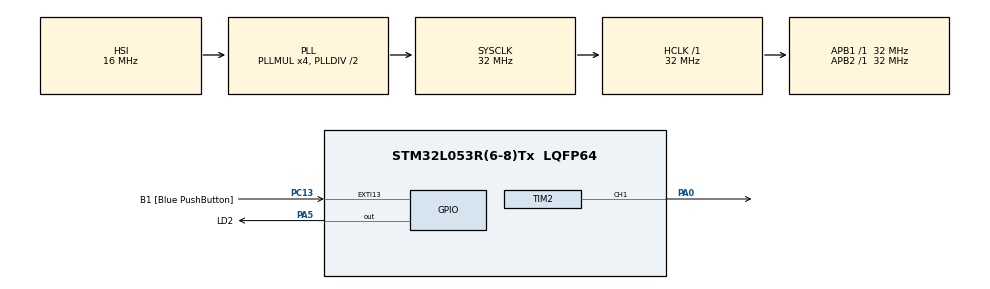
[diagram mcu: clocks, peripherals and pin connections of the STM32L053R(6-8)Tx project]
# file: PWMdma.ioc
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Dma.Request0=TIM2_CH1
Dma.TIM2_CH1.0.Direction=DMA_MEMORY_TO_PERIPH
Dma.TIM2_CH1.0.Instance=DMA1_Channel5
Dma.TIM2_CH1.0.MemDataAlignment=DMA_MDATAALIGN_HALFWORD
Dma.TIM2_CH1.0.MemInc=DMA_MINC_ENABLE
Dma.TIM2_CH1.0.Mode=DMA_NORMAL
Dma.TIM2_CH1.0.PeriphDataAlignment=DMA_PDATAALIGN_HALFWORD
Dma.TIM2_CH1.0.PeriphInc=DMA_PINC_DISABLE
Dma.TIM2_CH1.0.Priority=DMA_PRIORITY_LOW
Dma.TIM2_CH1.0.Request=DMA_REQUEST_8
Mcu.Family=STM32L0
Mcu.Name=STM32L053R(6-8)Tx
Mcu.Package=LQFP64
NVIC.DMA1_Channel4_5_6_7_IRQn=true\:0\:0\:false
PA0.Signal=S_TIM2_CH1
PA13.GPIO_Label=TMS
PA13.Mode=Serial_Wire
PA13.Signal=SYS_SWDIO
PA14.GPIO_Label=TCK
PA14.Mode=Serial_Wire
PA14.Signal=SYS_SWCLK
PA2.GPIO_Label=USART_TX
PA2.Signal=USART2_TX
PA3.GPIO_Label=USART_RX
PA3.Signal=USART2_RX
PA5.GPIO_Label=LD2
PA5.Signal=GPIO_Output
PC13.GPIO_Label=B1 [Blue PushButton]
PC13.GPIO_ModeDefaultEXTI=GPIO_MODE_EVT_RISING
PC13.Signal=GPXTI13
PC14-OSC32_IN.Signal=RCC_OSC32_IN
PC15-OSC32_OUT.Signal=RCC_OSC32_OUT
PH0-OSC_IN.Signal=RCC_OSC_IN
PH1-OSC_OUT.Signal=RCC_OSC_OUT
ProjectManager.TargetToolchain=EWARM
RCC.AHBFreq_Value=32000000
RCC.APB1Freq_Value=32000000
RCC.APB1TimFreq_Value=32000000
RCC.APB2Freq_Value=32000000
RCC.APB2TimFreq_Value=32000000
RCC.HCLKFreq_Value=32000000
RCC.HSE_VALUE=8000000
RCC.HSI16_VALUE=16000000
RCC.HSI48_VALUE=48000000
RCC.HSI_VALUE=16000000
RCC.LSEState=RCC_LSE_ON
RCC.LSE_VALUE=32768
RCC.MSI_VALUE=2097000
RCC.PLLMUL=RCC_PLLMUL_4
RCC.SYSCLKFreq_VALUE=32000000
RCC.SYSCLKSource=RCC_SYSCLKSOURCE_PLLCLK
RCC.VCOOutputFreq_Value=64000000
SH.S_TIM2_CH1.0=TIM2_CH1,PWM Generation1 CH1
TIM2.OCFastMode_PWM-PWM\ Generation1\ CH1=TIM_OCFAST_DISABLE
TIM2.Period=38
TIM2.Prescaler=0
TIM2.Pulse-PWM\ Generation1\ CH1=0
TIM2.TIM_MasterOutputTrigger=TIM_TRGO_RESET
TIM2.TIM_MasterSlaveMode=TIM_MASTERSLAVEMODE_DISABLE
VP_TIM2_VS_ClockSourceINT.Mode=Internal
board=NUCLEO-L053R8

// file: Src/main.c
/**
  ******************************************************************************
  * File Name          : main.c
  * Description        : Main program body
  ******************************************************************************
  *
  * COPYRIGHT(c) 2016 STMicroelectronics
  *
  * Redistribution and use in source and binary forms, with or without modification,
  * are permitted provided that the following conditions are met:
  *   1. Redistributions of source code must retain the above copyright notice,
  *      this list of conditions and the following disclaimer.
  *   2. Redistributions in binary form must reproduce the above copyright notice,
  *      this list of conditions and the following disclaimer in the documentation
  *      and/or other materials provided with the distribution.
  *   3. Neither the name of STMicroelectronics nor the names of its contributors
  *      may be used to endorse or promote products derived from this software
  *      without specific prior written permission.
  *
  * THIS SOFTWARE IS PROVIDED BY THE COPYRIGHT HOLDERS AND CONTRIBUTORS "AS IS"
  * AND ANY EXPRESS OR IMPLIED WARRANTIES, INCLUDING, BUT NOT LIMITED TO, THE
  * IMPLIED WARRANTIES OF MERCHANTABILITY AND FITNESS FOR A PARTICULAR PURPOSE ARE
  * DISCLAIMED. IN NO EVENT SHALL THE COPYRIGHT HOLDER OR CONTRIBUTORS BE LIABLE
  * FOR ANY DIRECT, INDIRECT, INCIDENTAL, SPECIAL, EXEMPLARY, OR CONSEQUENTIAL
  * DAMAGES (INCLUDING, BUT NOT LIMITED TO, PROCUREMENT OF SUBSTITUTE GOODS OR
  * SERVICES; LOSS OF USE, DATA, OR PROFITS; OR BUSINESS INTERRUPTION) HOWEVER
  * CAUSED AND ON ANY THEORY OF LIABILITY, WHETHER IN CONTRACT, STRICT LIABILITY,
  * OR TORT (INCLUDING NEGLIGENCE OR OTHERWISE) ARISING IN ANY WAY OUT OF THE USE
  * OF THIS SOFTWARE, EVEN IF ADVISED OF THE POSSIBILITY OF SUCH DAMAGE.
  *
  ******************************************************************************
  */
#include "stm32l0xx_hal.h"
#include "dma.h"
#include "tim.h"
#include "gpio.h"

/* USER CODE BEGIN Includes */
#include <string.h>
/* USER CODE END Includes */

/* USER CODE BEGIN PV */
/* Private variables ---------------------------------------------------------*/

/* USER CODE END PV */

void SystemClock_Config(void);

/* USER CODE BEGIN PFP */
/* Private function prototypes -----------------------------------------------*/

/* USER CODE END PFP */

/* USER CODE BEGIN 0 */
#define H_VAL 26
#define L_VAL 14
#define N_LEDS 24
#define BITS_PER_LED (3*8)
#define BIT_BUF_SIZE (N_LEDS * BITS_PER_LED)
uint16_t ws2812BitBuf[BIT_BUF_SIZE + 1]; //DMA transfer needs one byte more with ZERO, because it will be output after DMA transfer has finished

void ws2812_set_color(int led, uint8_t r, uint8_t g, uint8_t b)
{
  if (led >= N_LEDS) return;
  int i = led * BITS_PER_LED;
  uint8_t mask;
  mask = 0x80;
  while(mask) {
    ws2812BitBuf[i] = (mask & g)?H_VAL:L_VAL;
    mask >>= 1;
    i++;
  }
  mask = 0x80;
  while(mask) {
    ws2812BitBuf[i] = (mask & r)?H_VAL:L_VAL;
    mask >>= 1;
    i++;
  }
  mask = 0x80;
  while(mask) {
    ws2812BitBuf[i] = (mask & b)?H_VAL:L_VAL;
    mask >>= 1;
    i++;
  }
}
/* USER CODE END 0 */

int main(void)
{

  /* MCU Configuration----------------------------------------------------------*/

  /* Reset of all peripherals, Initializes the Flash interface and the Systick. */
  HAL_Init();

  /* Configure the system clock */
  SystemClock_Config();

  /* Initialize all configured peripherals */
  MX_GPIO_Init();
  MX_DMA_Init();
  MX_TIM2_Init();

  /* USER CODE BEGIN 2 */
  memset(ws2812BitBuf, 0, sizeof(ws2812BitBuf));
  for (int led = 0; led < N_LEDS; led++) ws2812_set_color(led, 2, 2, 2);
  HAL_TIM_PWM_Start_DMA(&htim2, TIM_CHANNEL_1, (uint32_t*)ws2812BitBuf, sizeof(ws2812BitBuf) / sizeof(ws2812BitBuf[0]));
  HAL_Delay(10);
  /* USER CODE END 2 */

  /* Infinite loop */
  while (1)
  {

  /* USER CODE BEGIN 3 */
    static int cursorled = 0;
    static uint8_t r = 0;
    static uint8_t g = 0;
    static uint8_t b = 0;
    static uint8_t state = 0;
    if (GPIO_PIN_SET == HAL_GPIO_ReadPin(B1_GPIO_Port, B1_Pin)) {
      for (int led = 0; led < N_LEDS; led++) ws2812_set_color(led, r, g, b);
      cursorled++;
      if (N_LEDS <= cursorled) {
        cursorled = 0;
      }
      switch (state) {
        case 0:
          r++;
          if (g) g--;
          b = 0;
          if (r == 255) {
            state++;
          }
          break;
        case 1:
          if (r) r--;
          g = 0;
          b++;
          if (b == 255) {
            state++;
          }
          break;
        case 2:
          r = 0;
          g++;
          if (b) b--;
          if (g == 255) {
            state++;
          }
          break;
        default:
          state = 0;
          break;
      }
      ws2812_set_color(cursorled, 255, 255, 255);
      HAL_TIM_PWM_Stop_DMA(&htim2, TIM_CHANNEL_1);
      HAL_TIM_PWM_Start_DMA(&htim2, TIM_CHANNEL_1, (uint32_t*)ws2812BitBuf, sizeof(ws2812BitBuf) / sizeof(ws2812BitBuf[0]));
      HAL_GPIO_TogglePin(LD2_GPIO_Port, LD2_Pin);
      HAL_Delay(50);

//      HAL_GPIO_WritePin(LD2_GPIO_Port, LD2_Pin, GPIO_PIN_SET);
    }
    else {
      HAL_GPIO_WritePin(LD2_GPIO_Port, LD2_Pin, GPIO_PIN_RESET);
    }
  }
  /* USER CODE END 3 */

}

/** System Clock Configuration
*/
void SystemClock_Config(void)
{

  RCC_OscInitTypeDef RCC_OscInitStruct;
  RCC_ClkInitTypeDef RCC_ClkInitStruct;

  __PWR_CLK_ENABLE();

  __HAL_PWR_VOLTAGESCALING_CONFIG(PWR_REGULATOR_VOLTAGE_SCALE1);

  RCC_OscInitStruct.OscillatorType = RCC_OSCILLATORTYPE_HSI;
  RCC_OscInitStruct.HSIState = RCC_HSI_ON;
  RCC_OscInitStruct.HSICalibrationValue = 16;
  RCC_OscInitStruct.PLL.PLLState = RCC_PLL_ON;
  RCC_OscInitStruct.PLL.PLLSource = RCC_PLLSOURCE_HSI;
  RCC_OscInitStruct.PLL.PLLMUL = RCC_PLLMUL_4;
  RCC_OscInitStruct.PLL.PLLDIV = RCC_PLLDIV_2;
  HAL_RCC_OscConfig(&RCC_OscInitStruct);

  RCC_ClkInitStruct.ClockType = RCC_CLOCKTYPE_SYSCLK;
  RCC_ClkInitStruct.SYSCLKSource = RCC_SYSCLKSOURCE_PLLCLK;
  RCC_ClkInitStruct.AHBCLKDivider = RCC_SYSCLK_DIV1;
  RCC_ClkInitStruct.APB1CLKDivider = RCC_HCLK_DIV1;
  RCC_ClkInitStruct.APB2CLKDivider = RCC_HCLK_DIV1;
  HAL_RCC_ClockConfig(&RCC_ClkInitStruct, FLASH_LATENCY_1);

  HAL_SYSTICK_Config(HAL_RCC_GetHCLKFreq()/1000);

  HAL_SYSTICK_CLKSourceConfig(SYSTICK_CLKSOURCE_HCLK);

  /* SysTick_IRQn interrupt configuration */
  HAL_NVIC_SetPriority(SysTick_IRQn, 0, 0);
}

/************************ (C) COPYRIGHT STMicroelectronics *****END OF FILE****/
